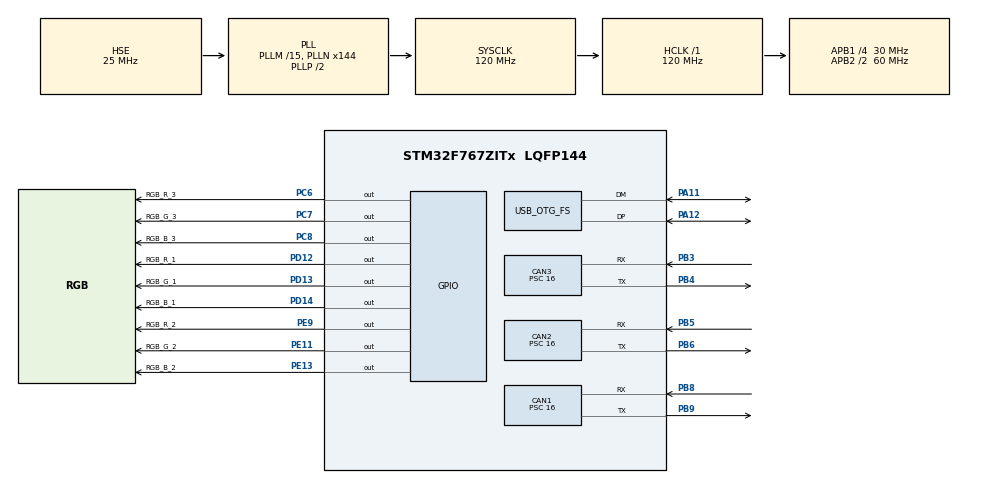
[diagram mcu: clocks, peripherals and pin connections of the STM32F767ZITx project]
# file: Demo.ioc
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CAN1.CalculateBaudRate=625000
CAN1.CalculateTimeBit=1600
CAN1.CalculateTimeQuantum=533.3333333333334
CAN1.Prescaler=16
CAN2.CalculateBaudRate=625000
CAN2.CalculateTimeBit=1600
CAN2.CalculateTimeQuantum=533.3333333333334
CAN2.Prescaler=16
CAN3.CalculateBaudRate=625000
CAN3.CalculateTimeBit=1600
CAN3.CalculateTimeQuantum=533.3333333333334
CAN3.Prescaler=16
Mcu.Family=STM32F7
Mcu.Name=STM32F767ZITx
Mcu.Package=LQFP144
NVIC.CAN1_RX0_IRQn=true\:0\:0\:false\:false\:true\:true\:true\:true
NVIC.CAN1_TX_IRQn=true\:0\:0\:false\:false\:true\:true\:true\:true
NVIC.CAN2_RX0_IRQn=true\:0\:0\:false\:false\:true\:true\:true\:true
NVIC.CAN2_TX_IRQn=true\:0\:0\:false\:false\:true\:true\:true\:true
NVIC.CAN3_RX0_IRQn=true\:0\:0\:false\:false\:true\:true\:true\:true
NVIC.CAN3_TX_IRQn=true\:0\:0\:false\:false\:true\:true\:true\:true
NVIC.OTG_FS_IRQn=true\:0\:0\:false\:false\:true\:false\:true\:true
NVIC.PriorityGroup=NVIC_PRIORITYGROUP_4
PA11.Mode=Device_Only
PA11.Signal=USB_OTG_FS_DM
PA12.Mode=Device_Only
PA12.Signal=USB_OTG_FS_DP
PA13.Mode=Serial_Wire
PA13.Signal=SYS_JTMS-SWDIO
PA14.Mode=Serial_Wire
PA14.Signal=SYS_JTCK-SWCLK
PB3.Mode=CAN_Activate
PB3.Signal=CAN3_RX
PB4.Mode=CAN_Activate
PB4.Signal=CAN3_TX
PB5.Mode=CAN_Activate
PB5.Signal=CAN2_RX
PB6.Mode=CAN_Activate
PB6.Signal=CAN2_TX
PB8.Mode=CAN_Activate
PB8.Signal=CAN1_RX
PB9.Mode=CAN_Activate
PB9.Signal=CAN1_TX
PC14/OSC32_IN.Mode=LSE-External-Oscillator
PC14/OSC32_IN.Signal=RCC_OSC32_IN
PC15/OSC32_OUT.Mode=LSE-External-Oscillator
PC15/OSC32_OUT.Signal=RCC_OSC32_OUT
PC6.GPIO_Label=RGB_R_3
PC6.Signal=GPIO_Output
PC7.GPIO_Label=RGB_G_3
PC7.Signal=GPIO_Output
PC8.GPIO_Label=RGB_B_3
PC8.Signal=GPIO_Output
PD12.GPIO_Label=RGB_R_1
PD12.Signal=GPIO_Output
PD13.GPIO_Label=RGB_G_1
PD13.Signal=GPIO_Output
PD14.GPIO_Label=RGB_B_1
PD14.Signal=GPIO_Output
PE11.GPIO_Label=RGB_G_2
PE11.Signal=GPIO_Output
PE13.GPIO_Label=RGB_B_2
PE13.Signal=GPIO_Output
PE9.GPIO_Label=RGB_R_2
PE9.Signal=GPIO_Output
PH0/OSC_IN.Mode=HSE-External-Oscillator
PH0/OSC_IN.Signal=RCC_OSC_IN
PH1/OSC_OUT.Mode=HSE-External-Oscillator
PH1/OSC_OUT.Signal=RCC_OSC_OUT
ProjectManager.HeapSize=0x2000
ProjectManager.StackSize=0x4000
ProjectManager.TargetToolchain=STM32CubeIDE
RCC.AHBFreq_Value=120000000
RCC.APB1CLKDivider=RCC_HCLK_DIV4
RCC.APB1Freq_Value=30000000
RCC.APB1TimFreq_Value=60000000
RCC.APB2CLKDivider=RCC_HCLK_DIV2
RCC.APB2Freq_Value=60000000
RCC.APB2TimFreq_Value=120000000
RCC.CortexFreq_Value=120000000
RCC.HCLKFreq_Value=120000000
RCC.HSE_VALUE=25000000
RCC.HSI_VALUE=16000000
RCC.PLLM=15
RCC.PLLN=144
RCC.PLLQ=5
RCC.SYSCLKFreq_VALUE=120000000
RCC.SYSCLKSource=RCC_SYSCLKSOURCE_PLLCLK
RCC.USBFreq_Value=48000000
RCC.VCOOutputFreq_Value=240000000
USB_DEVICE.CLASS_NAME_FS=CDC
USB_DEVICE.VirtualMode-CDC_FS=Cdc
USB_DEVICE.VirtualModeFS=Cdc_FS
USB_OTG_FS.VirtualMode=Device_Only
VP_RTC_VS_RTC_Activate.Mode=RTC_Enabled
VP_RTC_VS_RTC_Calendar.Mode=RTC_Calendar
VP_USB_DEVICE_VS_USB_DEVICE_CDC_FS.Mode=CDC_FS
board=custom

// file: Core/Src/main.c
/* USER CODE BEGIN Header */
/**
  ******************************************************************************
  * @file           : main.c
  * @brief          : Main program body
  ******************************************************************************
  * @attention
  *
  * Copyright (c) 2023 STMicroelectronics.
  * All rights reserved.
  *
  * This software is licensed under terms that can be found in the LICENSE file
  * in the root directory of this software component.
  * If no LICENSE file comes with this software, it is provided AS-IS.
  *
  ******************************************************************************
  */
/* USER CODE END Header */
#include "main.h"
#include "can.h"
#include "rtc.h"
#include "usb_device.h"
#include "gpio.h"

/* USER CODE BEGIN Includes */
#include "utils.h"
/* USER CODE END Includes */

void SystemClock_Config(void);

int main(void)
{

  /* MCU Configuration--------------------------------------------------------*/

  /* Reset of all peripherals, Initializes the Flash interface and the Systick. */
  HAL_Init();

  /* Configure the system clock */
  SystemClock_Config();

  /* Initialize all configured peripherals */
  MX_GPIO_Init();
  MX_CAN1_Init();
  MX_CAN2_Init();
  MX_CAN3_Init();
  MX_USB_DEVICE_Init();
  MX_RTC_Init();
  /* USER CODE BEGIN 2 */

  uint8_t buf[30];
	CAN_RxHeaderTypeDef  rx_header;
	uint8_t  rx_data[8];
	uint8_t Frame[30];
	uint8_t FrameLength;
  uint8_t data[8];
  CAN_TxHeaderTypeDef   tx_header;

  /* USER CODE END 2 */
  allLEDsOff();
  CAN1_Config_Filters();
  CAN2_Config_Filters();
  CAN3_Config_Filters();
  vcp_init ();	//initialised FiFo

  /* Infinite loop */
  /* USER CODE BEGIN WHILE */
uint8_t len;
  while (1)
  {
    /* USER CODE END WHILE */
	  // VCP demonstration - Echo all data received over VCP back to the host
	      len = vcp_recv (buf, 30);  // Read up to 1000 bytes
	      if (len > 0)
	      {
	    	  if (buf[0] == 0x74 || buf[0] == 0x54)
	    	  {
	    		  buildCanFrameUSB(buf, data, &tx_header);
	    		  CANTransmit(CAN1, data, tx_header);
	    		  arr[count] = tx_header.StdId;
	    		  count++;
	    	  }
	      }

  /* USER CODE END 3 */

  }
  /*CANTransmit(CAN1, CAN_ID_CELLINFO1, buf, 5);
  HAL_Delay(2000);*/

}

void SystemClock_Config(void)
{
  RCC_OscInitTypeDef RCC_OscInitStruct = {0};
  RCC_ClkInitTypeDef RCC_ClkInitStruct = {0};

  /** Configure LSE Drive Capability
  */
  HAL_PWR_EnableBkUpAccess();

  /** Configure the main internal regulator output voltage
  */
  __HAL_RCC_PWR_CLK_ENABLE();
  __HAL_PWR_VOLTAGESCALING_CONFIG(PWR_REGULATOR_VOLTAGE_SCALE3);

  /** Initializes the RCC Oscillators according to the specified parameters
  * in the RCC_OscInitTypeDef structure.
  */
  RCC_OscInitStruct.OscillatorType = RCC_OSCILLATORTYPE_LSI|RCC_OSCILLATORTYPE_HSE;
  RCC_OscInitStruct.HSEState = RCC_HSE_ON;
  RCC_OscInitStruct.LSIState = RCC_LSI_ON;
  RCC_OscInitStruct.PLL.PLLState = RCC_PLL_ON;
  RCC_OscInitStruct.PLL.PLLSource = RCC_PLLSOURCE_HSE;
  RCC_OscInitStruct.PLL.PLLM = 15;
  RCC_OscInitStruct.PLL.PLLN = 144;
  RCC_OscInitStruct.PLL.PLLP = RCC_PLLP_DIV2;
  RCC_OscInitStruct.PLL.PLLQ = 5;
  RCC_OscInitStruct.PLL.PLLR = 2;
  if (HAL_RCC_OscConfig(&RCC_OscInitStruct) != HAL_OK)
  {
    Error_Handler();
  }

  /** Initializes the CPU, AHB and APB buses clocks
  */
  RCC_ClkInitStruct.ClockType = RCC_CLOCKTYPE_HCLK|RCC_CLOCKTYPE_SYSCLK
                              |RCC_CLOCKTYPE_PCLK1|RCC_CLOCKTYPE_PCLK2;
  RCC_ClkInitStruct.SYSCLKSource = RCC_SYSCLKSOURCE_PLLCLK;
  RCC_ClkInitStruct.AHBCLKDivider = RCC_SYSCLK_DIV1;
  RCC_ClkInitStruct.APB1CLKDivider = RCC_HCLK_DIV4;
  RCC_ClkInitStruct.APB2CLKDivider = RCC_HCLK_DIV2;

  if (HAL_RCC_ClockConfig(&RCC_ClkInitStruct, FLASH_LATENCY_3) != HAL_OK)
  {
    Error_Handler();
  }
}

void Error_Handler(void)
{
  __disable_irq();
  while (1)
  {
  }
}
